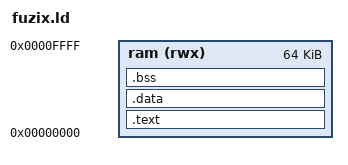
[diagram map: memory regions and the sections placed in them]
STARTUP(crt0.o)
OUTPUT_ARCH(i8086)


SEARCH_DIR(.)

MEMORY
{
  ram (rwx) : ORIGIN = 0x0000, LENGTH = 0x10000
}

/*
 * stick everything in ram (of course)
 */
SECTIONS
{
  .text :
  {
    CREATE_OBJECT_SYMBOLS
    *(.text .text.*)

    . = ALIGN(0x4);
    /* These are for running static constructors and destructors under ELF.  */

    *(.rodata .rodata.*)

    . = ALIGN(0x4);
    *(.gcc_except_table)

    . = ALIGN(0x4);
    *(.eh_frame)

    . = ALIGN(0x4);
    _etext = .;
    *(.lit)
  } > ram

  .data :
  {
    *(.got.plt) *(.got)
    *(.shdata)
    *(.data .data.*)
    _edata = .;
  } > ram

  .bss :
  {
    . = ALIGN(0x4);
    __bss_start = . ;
    *(.shbss)
    *(.bss .bss.*)
    *(COMMON)
    _end =  ALIGN (0x8);
    __end = _end;
  } > ram

  .stab 0 (NOLOAD) :
  {
    *(.stab)
  }

  .stabstr 0 (NOLOAD) :
  {
    *(.stabstr)
  }
}
